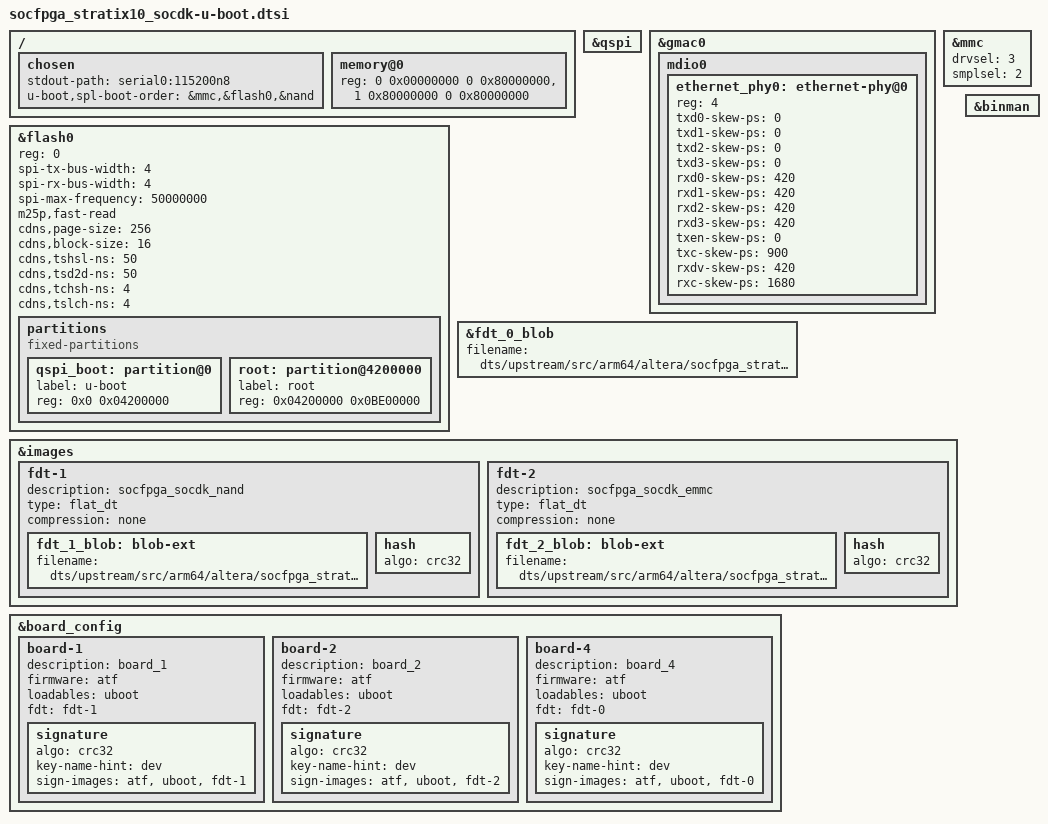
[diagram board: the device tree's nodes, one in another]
// SPDX-License-Identifier: GPL-2.0+
/*
 * U-Boot additions
 *
 * Copyright (C) 2019-2022 Intel Corporation <www.intel.com>
 * Copyright (C) 2026 Altera Corporation <www.altera.com>
 */

#include "socfpga_stratix10-u-boot.dtsi"

/{
	chosen {
		stdout-path = "serial0:115200n8";
		u-boot,spl-boot-order = &mmc,&flash0,&nand;
	};

	memory@0 {
		/* 4GB */
		reg = <0 0x00000000 0 0x80000000>,
		      <1 0x80000000 0 0x80000000>;
	};
};

&qspi {
	status = "okay";
};

&gmac0 {
	mdio0 {
		ethernet_phy0: ethernet-phy@0 {
			reg = <4>;
			txd0-skew-ps = <0>; /* -420ps */
			txd1-skew-ps = <0>; /* -420ps */
			txd2-skew-ps = <0>; /* -420ps */
			txd3-skew-ps = <0>; /* -420ps */
			rxd0-skew-ps = <420>; /* 0ps */
			rxd1-skew-ps = <420>; /* 0ps */
			rxd2-skew-ps = <420>; /* 0ps */
			rxd3-skew-ps = <420>; /* 0ps */
			txen-skew-ps = <0>; /* -420ps */
			txc-skew-ps = <900>; /* 0ps */
			rxdv-skew-ps = <420>; /* 0ps */
			rxc-skew-ps = <1680>; /* 780ps */
		};
	};
};

&mmc {
	drvsel = <3>;
	smplsel = <2>;
	bootph-all;
};

&qspi {
	/delete-property/ clocks;
};

&flash0 {
	reg = <0>;
	spi-tx-bus-width = <4>;
	spi-rx-bus-width = <4>;
	spi-max-frequency = <50000000>;
	bootph-all;

	m25p,fast-read;
	cdns,page-size = <256>;
	cdns,block-size = <16>;
	cdns,read-delay = <1>;
	cdns,tshsl-ns = <50>;
	cdns,tsd2d-ns = <50>;
	cdns,tchsh-ns = <4>;
	cdns,tslch-ns = <4>;
	/delete-property/ cdns,read-delay;

	partitions {
		compatible = "fixed-partitions";
		#address-cells = <1>;
		#size-cells = <1>;

		qspi_boot: partition@0 {
			label = "u-boot";
			reg = <0x0 0x04200000>;
		};

		root: partition@4200000 {
			label = "root";
			reg = <0x04200000 0x0BE00000>;
		};
	};
};

&fdt_0_blob {
	filename = "dts/upstream/src/arm64/altera/socfpga_stratix10_socdk.dtb";
};

&images {
	fdt-1 {
		description = "socfpga_socdk_nand";
		type = "flat_dt";
		compression = "none";
		fdt_1_blob: blob-ext {
			filename = "dts/upstream/src/arm64/altera/socfpga_stratix10_socdk_nand.dtb";
		};
		hash {
			algo = "crc32";
		};
	};

	fdt-2 {
		description = "socfpga_socdk_emmc";
		type = "flat_dt";
		compression = "none";
		fdt_2_blob: blob-ext {
			filename = "dts/upstream/src/arm64/altera/socfpga_stratix10_socdk_emmc.dtb";
		};
		hash {
			algo = "crc32";
		};
	};
};

&board_config {
	board-1 {
		description = "board_1";
		firmware = "atf";
		loadables = "uboot";
		fdt = "fdt-1";
		signature {
			algo = "crc32";
			key-name-hint = "dev";
			sign-images = "atf", "uboot", "fdt-1";
		};
	};

	board-2 {
		description = "board_2";
		firmware = "atf";
		loadables = "uboot";
		fdt = "fdt-2";
		signature {
			algo = "crc32";
			key-name-hint = "dev";
			sign-images = "atf", "uboot", "fdt-2";
		};
	};

	board-4 {
		description = "board_4";
		firmware = "atf";
		loadables = "uboot";
		fdt = "fdt-0";
		signature {
			algo = "crc32";
			key-name-hint = "dev";
			sign-images = "atf", "uboot", "fdt-0";
		};
	};
};

&binman {
	/delete-node/ kernel;
};
